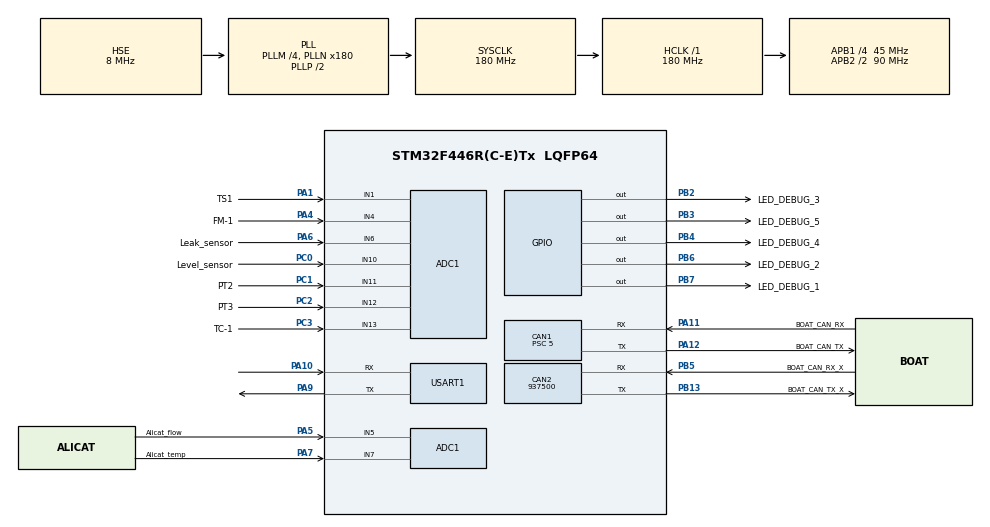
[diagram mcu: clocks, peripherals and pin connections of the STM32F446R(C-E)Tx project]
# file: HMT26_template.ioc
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ADC1.Channel-0\#ChannelRegularConversion=ADC_CHANNEL_4
ADC1.ClockPrescaler=ADC_CLOCK_SYNC_PCLK_DIV4
ADC1.ContinuousConvMode=DISABLE
ADC1.DMAContinuousRequests=DISABLE
ADC1.DiscontinuousConvMode=DISABLE
ADC1.NbrOfConversion=1
ADC1.NbrOfConversionFlag=1
ADC1.Rank-0\#ChannelRegularConversion=1
ADC1.SamplingTime-0\#ChannelRegularConversion=ADC_SAMPLETIME_3CYCLES
ADC1.ScanConvMode=DISABLE
ADC1.master=1
CAN1.ABOM=ENABLE
CAN1.AWUM=ENABLE
CAN1.BS1=CAN_BS1_9TQ
CAN1.BS2=CAN_BS2_8TQ
CAN1.CalculateBaudRate=500000
CAN1.CalculateTimeBit=2000
CAN1.CalculateTimeQuantum=111.11111111111111
CAN1.NART=ENABLE
CAN1.Prescaler=5
CAN2.CalculateBaudRate=937500
CAN2.CalculateTimeBit=1066
CAN2.CalculateTimeQuantum=355.55555555555554
Mcu.Family=STM32F4
Mcu.Name=STM32F446R(C-E)Tx
Mcu.Package=LQFP64
NVIC.CAN1_RX0_IRQn=true\:0\:0\:false\:false\:true\:true\:true\:true
NVIC.CAN1_TX_IRQn=true\:0\:0\:false\:false\:true\:true\:true\:true
NVIC.PriorityGroup=NVIC_PRIORITYGROUP_4
NVIC.TIM1_UP_TIM10_IRQn=true\:15\:0\:false\:false\:true\:false\:true\:true
NVIC.TIM2_IRQn=true\:5\:0\:true\:false\:true\:true\:true\:true
NVIC.TIM3_IRQn=true\:5\:0\:true\:false\:true\:true\:true\:true
NVIC.TIM4_IRQn=true\:5\:0\:true\:false\:true\:true\:true\:true
NVIC.TIM8_TRG_COM_TIM14_IRQn=true\:5\:0\:true\:false\:true\:true\:true\:true
NVIC.TIM8_UP_TIM13_IRQn=true\:5\:0\:true\:false\:true\:true\:true\:true
NVIC.TimeBase=TIM1_UP_TIM10_IRQn
NVIC.TimeBaseIP=TIM1
PA1.GPIO_Label=TS1
PA1.Signal=SharedAnalog_PA1
PA10.Mode=Asynchronous
PA10.Signal=USART1_RX
PA11.GPIO_Label=BOAT_CAN_RX
PA11.Mode=CAN_Activate
PA11.Signal=CAN1_RX
PA12.GPIO_Label=BOAT_CAN_TX
PA12.Mode=CAN_Activate
PA12.Signal=CAN1_TX
PA13.Mode=Serial_Wire
PA13.Signal=SYS_JTMS-SWDIO
PA14.Mode=Serial_Wire
PA14.Signal=SYS_JTCK-SWCLK
PA4.GPIO_Label=FM-1
PA4.Signal=SharedAnalog_PA4
PA5.GPIO_Label=Alicat_flow
PA5.Signal=SharedAnalog_PA5
PA6.GPIO_Label=Leak_sensor  
PA6.Signal=SharedAnalog_PA6
PA7.GPIO_Label=Alicat_temp
PA7.Signal=SharedAnalog_PA7
PA9.Mode=Asynchronous
PA9.Signal=USART1_TX
PB13.GPIO_Label=BOAT_CAN_TX_X
PB13.Mode=CAN_Activate
PB13.Signal=CAN2_TX
PB2.GPIO_Label=LED_DEBUG_3
PB2.Signal=GPIO_Output
PB3.GPIO_Label=LED_DEBUG_5
PB3.Signal=GPIO_Output
PB4.GPIO_Label=LED_DEBUG_4
PB4.Signal=GPIO_Output
PB5.GPIO_Label=BOAT_CAN_RX_X
PB5.Mode=CAN_Activate
PB5.Signal=CAN2_RX
PB6.GPIO_Label=LED_DEBUG_2
PB6.Signal=GPIO_Output
PB7.GPIO_Label=LED_DEBUG_1
PB7.Signal=GPIO_Output
PC0.GPIO_Label=Level_sensor
PC0.Signal=SharedAnalog_PC0
PC1.GPIO_Label=PT2
PC1.Signal=SharedAnalog_PC1
PC2.GPIO_Label=PT3
PC2.Signal=SharedAnalog_PC2
PC3.GPIO_Label=TC-1
PC3.Signal=SharedAnalog_PC3
PH0-OSC_IN.Mode=HSE-External-Oscillator
PH0-OSC_IN.Signal=RCC_OSC_IN
PH1-OSC_OUT.Mode=HSE-External-Oscillator
PH1-OSC_OUT.Signal=RCC_OSC_OUT
ProjectManager.HeapSize=0x200
ProjectManager.StackSize=0x400
ProjectManager.TargetToolchain=CMake
RCC.AHBFreq_Value=180000000
RCC.APB1CLKDivider=RCC_HCLK_DIV4
RCC.APB1Freq_Value=45000000
RCC.APB1TimFreq_Value=90000000
RCC.APB2CLKDivider=RCC_HCLK_DIV2
RCC.APB2Freq_Value=90000000
RCC.APB2TimFreq_Value=180000000
RCC.CortexFreq_Value=180000000
RCC.HCLKFreq_Value=180000000
RCC.HSE_VALUE=8000000
RCC.HSICalibrationValue=12
RCC.PLLM=4
RCC.PLLN=180
RCC.PLLSourceVirtual=RCC_PLLSOURCE_HSE
RCC.SYSCLKFreq_VALUE=180000000
RCC.SYSCLKSource=RCC_SYSCLKSOURCE_PLLCLK
RCC.USBFreq_Value=180000000
RCC.VCOOutputFreq_Value=360000000
SH.SharedAnalog_PA1.0=GPIO_Analog
SH.SharedAnalog_PA1.1=ADC1_IN1,IN1
SH.SharedAnalog_PA4.0=GPIO_Analog
SH.SharedAnalog_PA4.1=ADC1_IN4,IN4
SH.SharedAnalog_PA5.0=GPIO_Analog
SH.SharedAnalog_PA5.1=ADC1_IN5,IN5
SH.SharedAnalog_PA6.0=GPIO_Analog
SH.SharedAnalog_PA6.1=ADC1_IN6,IN6
SH.SharedAnalog_PA7.0=GPIO_Analog
SH.SharedAnalog_PA7.1=ADC1_IN7,IN7
SH.SharedAnalog_PC0.0=GPIO_Analog
SH.SharedAnalog_PC0.1=ADC1_IN10,IN10
SH.SharedAnalog_PC1.0=GPIO_Analog
SH.SharedAnalog_PC1.1=ADC1_IN11,IN11
SH.SharedAnalog_PC2.0=GPIO_Analog
SH.SharedAnalog_PC2.1=ADC1_IN12,IN12
SH.SharedAnalog_PC3.0=GPIO_Analog
SH.SharedAnalog_PC3.1=ADC1_IN13,IN13
TIM13.Period=100
TIM13.Prescaler=8000-1
TIM14.Period=100
TIM14.Prescaler=8000-1
TIM2.AutoReloadPreload=TIM_AUTORELOAD_PRELOAD_DISABLE
TIM2.Period=250
TIM2.Prescaler=8000-1
TIM3.AutoReloadPreload=TIM_AUTORELOAD_PRELOAD_DISABLE
TIM3.Period=250
TIM3.Prescaler=8000-1
TIM4.Period=100
TIM4.Prescaler=8000-1
USART1.VirtualMode=VM_ASYNC
VP_SYS_VS_tim1.Mode=TIM1
VP_TIM13_VS_ClockSourceINT.Mode=Enable_Timer
VP_TIM14_VS_ClockSourceINT.Mode=Enable_Timer
VP_TIM2_VS_ClockSourceINT.Mode=Internal
VP_TIM3_VS_ClockSourceINT.Mode=Internal
VP_TIM4_VS_ClockSourceINT.Mode=Internal
board=custom

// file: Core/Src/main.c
/* USER CODE BEGIN Header */
/**
  ******************************************************************************
  * @file           : main.c
  * @brief          : Main program body
  ******************************************************************************
  * @attention
  *
  * Copyright (c) 2026 STMicroelectronics.
  * All rights reserved.
  *
  * This software is licensed under terms that can be found in the LICENSE file
  * in the root directory of this software component.
  * If no LICENSE file comes with this software, it is provided AS-IS.
  *
  ******************************************************************************
  */
/* USER CODE END Header */
#include "main.h"
#include "adc.h"
#include "can.h"
#include "tim.h"
#include "usart.h"
#include "gpio.h"

/* USER CODE BEGIN Includes */
#include "app.h"

/* USER CODE END Includes */

/* USER CODE BEGIN PV */
uint8_t status_changed_flag = 0;
/* USER CODE END PV */

void SystemClock_Config(void);

int main(void)
{

  /* MCU Configuration--------------------------------------------------------*/

  /* Reset of all peripherals, Initializes the Flash interface and the Systick. */
  HAL_Init();

  /* Configure the system clock */
  SystemClock_Config();

  /* Initialize all configured peripherals */
  MX_GPIO_Init();
  MX_USART1_UART_Init();
  MX_CAN2_Init();
  MX_TIM2_Init();
  MX_TIM3_Init();
  MX_TIM4_Init();
  MX_TIM13_Init();
  MX_TIM14_Init();
  MX_ADC1_Init();
  MX_CAN1_Init();
  /* USER CODE BEGIN 2 */
  app_init();

  /* USER CODE END 2 */

  /* Infinite loop */
  while (1)
  {

    /* USER CODE BEGIN 3 */
    app_loop();
  }
  /* USER CODE END 3 */
}

void SystemClock_Config(void)
{
  RCC_OscInitTypeDef RCC_OscInitStruct = {0};
  RCC_ClkInitTypeDef RCC_ClkInitStruct = {0};

  /** Configure the main internal regulator output voltage
  */
  __HAL_RCC_PWR_CLK_ENABLE();
  __HAL_PWR_VOLTAGESCALING_CONFIG(PWR_REGULATOR_VOLTAGE_SCALE1);

  /** Initializes the RCC Oscillators according to the specified parameters
  * in the RCC_OscInitTypeDef structure.
  */
  RCC_OscInitStruct.OscillatorType = RCC_OSCILLATORTYPE_HSE;
  RCC_OscInitStruct.HSEState = RCC_HSE_ON;
  RCC_OscInitStruct.PLL.PLLState = RCC_PLL_ON;
  RCC_OscInitStruct.PLL.PLLSource = RCC_PLLSOURCE_HSE;
  RCC_OscInitStruct.PLL.PLLM = 4;
  RCC_OscInitStruct.PLL.PLLN = 180;
  RCC_OscInitStruct.PLL.PLLP = RCC_PLLP_DIV2;
  RCC_OscInitStruct.PLL.PLLQ = 2;
  RCC_OscInitStruct.PLL.PLLR = 2;
  if (HAL_RCC_OscConfig(&RCC_OscInitStruct) != HAL_OK)
  {
    Error_Handler();
  }

  /** Activate the Over-Drive mode
  */
  if (HAL_PWREx_EnableOverDrive() != HAL_OK)
  {
    Error_Handler();
  }

  /** Initializes the CPU, AHB and APB buses clocks
  */
  RCC_ClkInitStruct.ClockType = RCC_CLOCKTYPE_HCLK|RCC_CLOCKTYPE_SYSCLK
                              |RCC_CLOCKTYPE_PCLK1|RCC_CLOCKTYPE_PCLK2;
  RCC_ClkInitStruct.SYSCLKSource = RCC_SYSCLKSOURCE_PLLCLK;
  RCC_ClkInitStruct.AHBCLKDivider = RCC_SYSCLK_DIV1;
  RCC_ClkInitStruct.APB1CLKDivider = RCC_HCLK_DIV4;
  RCC_ClkInitStruct.APB2CLKDivider = RCC_HCLK_DIV2;

  if (HAL_RCC_ClockConfig(&RCC_ClkInitStruct, FLASH_LATENCY_5) != HAL_OK)
  {
    Error_Handler();
  }
}

void HAL_TIM_PeriodElapsedCallback(TIM_HandleTypeDef *htim)
{
  if (htim->Instance == TIM1)
  {
    HAL_IncTick();
  }
}

void Error_Handler(void)
{
  __disable_irq();
  while (1)
  {
  }
}
